AUTOSAR XML (schema 4-3-0)
package /FVT_NVM_Impl_ARPkg
  swc implementation Impl_SWC_NVM_type: programming-language=C, sw-version=1.0.0, vendor-id=0, behavior=SWC_NVM_type_IB
    code-descriptors:
      code NVSRC: artifact-descriptors=autosar-engineering-object={short-label=EngObj, category=SWSRC}
    resource consumption ResourceConsumption
      memory section MEMsec_SWC_NVM: size=0, sw-addrmethod=CODE, symbol=CODE
package /FVT_NVM_Infertace_ARPkg
  nv data interface IF_NVM: is-service=true
    nv-datas:
      data NV_FVTDataArray: type=u8_FVTNVMArray1024_type, init-value=1024 x 0
  client server interface IF_NVMReadCDD_Inner
    operation NVM_ReadOperation
  client server interface IF_NVMWriteCDD_Inner
    operation NVM_WriteOperation
  sender receiver interface IF_NVMRead
    data u8Array1024_NVMReadData: type=u8_FVTNVMArray1024_type
  impl type u8_FVTNVMArray1024_type: category=ARRAY
    element NVM_Data: category=VALUE, array-size=1024, array-size-semantics=FIXED-SIZE, base-type=uint8
package /FVT_NVM_SWC_ARPkg
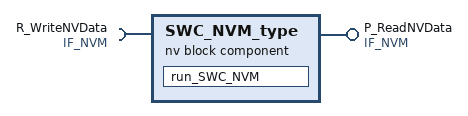
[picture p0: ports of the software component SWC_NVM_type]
  nv block sw component type SWC_NVM_type
    provide port P_ReadNVData: provided-interface=IF_NVM
    require port R_WriteNVData: required-interface=IF_NVM
    behavior SWC_NVM_type_IB: handle-termination-and-restart=NO-SUPPORT
      data received event DRE_StoreNVBlock: start-on-event=run_SWC_NVM, data=R_WriteNVData.NV_FVTDataArray
      runnable run_SWC_NVM
    nv block descriptor FVT_NvmWriteDescriptor: nv-block-data-mapping{nv-ram-block-element=RamBlock_FVT, read-nv-data=P_ReadNVData.NV_FVTDataArray, written-nv-data=R_WriteNVData.NV_FVTDataArray}, support-dirty-flag=true
      nv block needs FVT_NvmWriteNeed:
        calc-ram-block-crc=false
        check-static-block-id=false
        n-data-sets=0
        n-rom-blocks=0
        readonly=false
        reliability=NO-PROTECTION
        resistant-to-changed-sw=false
        restore-at-start=true
        select-block-for-first-init-all=false
        store-at-shutdown=true
        store-cyclic=false
        store-emergency=false
        store-immediate=true
        use-auto-validation-at-shut-down=false
        use-crc-comp-mechanism=false
        write-only-once=false
        write-verification=false
        writing-frequency=0
        writing-priority=LOW
      ram block RamBlock_FVT: type=u8_FVTNVMArray1024_type
      rom block RomBlock_FVT: data-constr=uint8, type=u8_FVTNVMArray1024_type, init-value=1024 x 0
